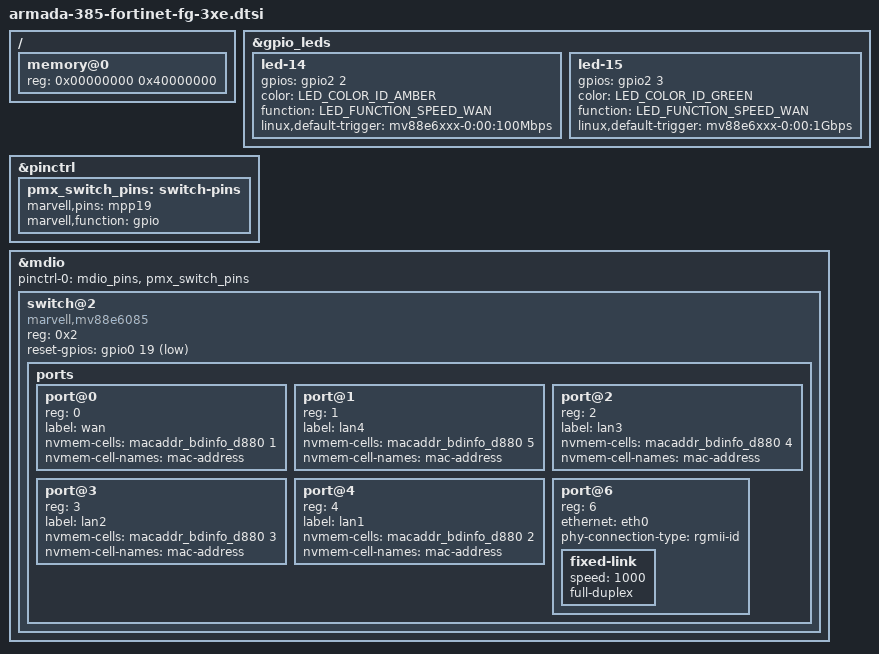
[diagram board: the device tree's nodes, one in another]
// SPDX-License-Identifier: GPL-2.0-or-later OR MIT

#include "armada-385-fortinet-fg-xxe.dtsi"

/ {
	memory@0 {
		device_type = "memory";
		reg = <0x00000000 0x40000000>; /* 1GB */
	};
};

&gpio_leds {
	led-14 {
		gpios = <&gpio2 2 GPIO_ACTIVE_HIGH>;
		color = <LED_COLOR_ID_AMBER>;
		function = LED_FUNCTION_SPEED_WAN;
		linux,default-trigger = "mv88e6xxx-0:00:100Mbps";
	};

	led-15 {
		gpios = <&gpio2 3 GPIO_ACTIVE_HIGH>;
		color = <LED_COLOR_ID_GREEN>;
		function = LED_FUNCTION_SPEED_WAN;
		linux,default-trigger = "mv88e6xxx-0:00:1Gbps";
	};
};

&pinctrl {
	pmx_switch_pins: switch-pins {
		marvell,pins = "mpp19";
		marvell,function = "gpio";
	};
};

&mdio {
	pinctrl-names = "default";
	pinctrl-0 = <&mdio_pins>, <&pmx_switch_pins>;

	/* Marvell 88E6176 */
	switch@2 {
		compatible = "marvell,mv88e6085";
		reg = <0x2>;
		reset-gpios = <&gpio0 19 GPIO_ACTIVE_LOW>;

		ports {
			#address-cells = <1>;
			#size-cells = <0>;

			port@0 {
				reg = <0>;
				label = "wan";
				nvmem-cells = <&macaddr_bdinfo_d880 1>;
				nvmem-cell-names = "mac-address";
			};

			port@1 {
				reg = <1>;
				label = "lan4";
				nvmem-cells = <&macaddr_bdinfo_d880 5>;
				nvmem-cell-names = "mac-address";
			};

			port@2 {
				reg = <2>;
				label = "lan3";
				nvmem-cells = <&macaddr_bdinfo_d880 4>;
				nvmem-cell-names = "mac-address";
			};

			port@3 {
				reg = <3>;
				label = "lan2";
				nvmem-cells = <&macaddr_bdinfo_d880 3>;
				nvmem-cell-names = "mac-address";
			};

			port@4 {
				reg = <4>;
				label = "lan1";
				nvmem-cells = <&macaddr_bdinfo_d880 2>;
				nvmem-cell-names = "mac-address";
			};

			port@6 {
				reg = <6>;
				ethernet = <&eth0>;
				phy-connection-type = "rgmii-id";

				fixed-link {
					speed = <1000>;
					full-duplex;
				};
			};
		};
	};
};
